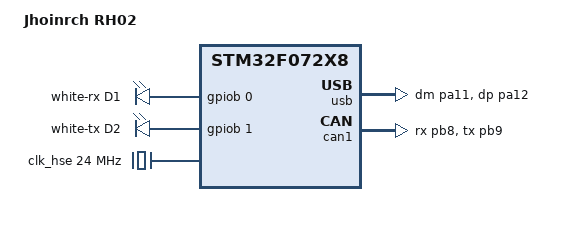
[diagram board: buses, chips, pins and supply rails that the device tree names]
/*
 * SPDX-FileCopyrightText: Copyright The Zephyr Project Contributors
 * SPDX-License-Identifier: Apache-2.0
 */

/dts-v1/;

#include <st/f0/stm32f072X8.dtsi>
#include <st/f0/stm32f072c(8-b)tx-pinctrl.dtsi>

/ {
	model = "Jhoinrch RH02";
	compatible = "jhoinrch,rh02";

	chosen {
		zephyr,sram = &sram0;
		zephyr,flash = &flash0;
		zephyr,canbus = &can1;
	};

	aliases {
		led0 = &led_rx;
		led1 = &led_tx;
	};

	leds: leds {
		compatible = "gpio-leds";

		led_rx: led_1 {
			gpios = <&gpiob 0 GPIO_ACTIVE_HIGH>;
			label = "white-rx D1";
		};

		led_tx: led_2 {
			gpios = <&gpiob 1 GPIO_ACTIVE_HIGH>;
			label = "white-tx D2";
		};
	};
};

&clk_hse {
	/* External 24 MHz crystal used to drive PLL */
	status = "okay";
	clock-frequency = <DT_FREQ_M(24)>;
};

/* Adjust the PLL for a SYSTEM Clock of 48 MHz  */
&pll {
	prediv = <1>;
	mul = <2>;
	clocks = <&clk_hse>;
	status = "okay";
};

&rcc {
	clocks = <&pll>;
	clock-frequency = <DT_FREQ_M(48)>;
	ahb-prescaler = <1>;
	apb1-prescaler = <1>;
};

zephyr_udc0: &usb {
	pinctrl-0 = <&usb_dm_pa11 &usb_dp_pa12>;
	pinctrl-names = "default";
	status = "okay";
};

&can1 {
	pinctrl-0 = <&can_rx_pb8 &can_tx_pb9>;
	pinctrl-names = "default";
	status = "okay";

	can-transceiver {
		max-bitrate = <1000000>;
	};
};
